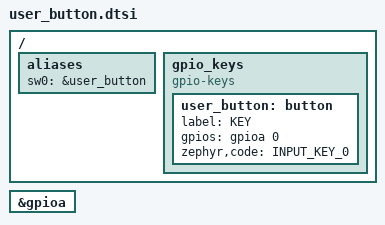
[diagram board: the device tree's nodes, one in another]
/*
 * Copyright (c) 2025 TiaC Systems
 * SPDX-License-Identifier: Apache-2.0
 */

#include <zephyr/dt-bindings/gpio/gpio.h>
#include <zephyr/dt-bindings/input/input-event-codes.h>

/ {
	aliases {
		sw0 = &user_button;
	};

	gpio_keys {
		compatible = "gpio-keys";
		user_button: button {
			label = "KEY";
			gpios = <&gpioa 0 (GPIO_ACTIVE_HIGH | GPIO_PULL_DOWN)>;
			zephyr,code = <INPUT_KEY_0>;
		};
	};
};

&gpioa {
	status = "okay";
};
